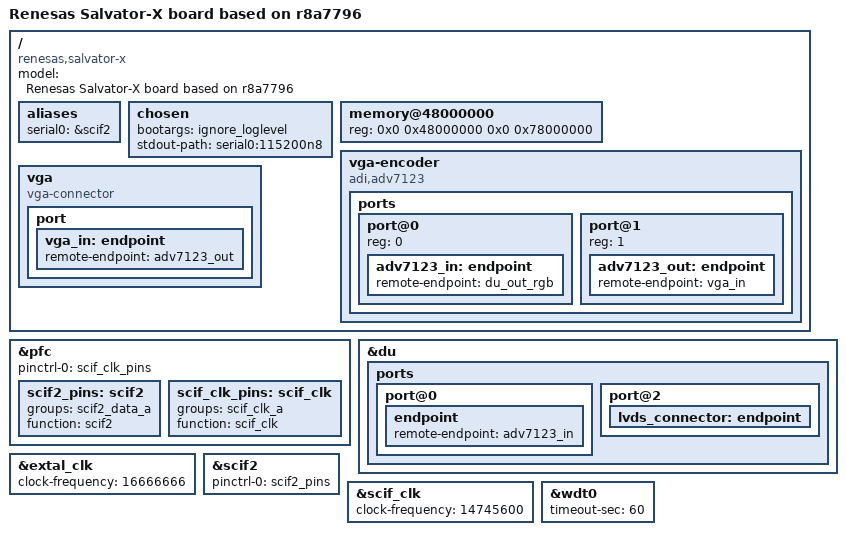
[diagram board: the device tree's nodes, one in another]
/*
 * Device Tree Source for the Salvator-X board
 *
 * Copyright (C) 2016 Renesas Electronics Corp.
 *
 * This file is licensed under the terms of the GNU General Public License
 * version 2.  This program is licensed "as is" without any warranty of any
 * kind, whether express or implied.
 */

/dts-v1/;
#include "r8a7796.dtsi"

/ {
	model = "Renesas Salvator-X board based on r8a7796";
	compatible = "renesas,salvator-x", "renesas,r8a7796";

	aliases {
		serial0 = &scif2;
	};

	chosen {
		bootargs = "ignore_loglevel";
		stdout-path = "serial0:115200n8";
	};

	memory@48000000 {
		device_type = "memory";
		/* first 128MB is reserved for secure area. */
		reg = <0x0 0x48000000 0x0 0x78000000>;
	};

	vga-encoder {
		compatible = "adi,adv7123";

		ports {
			#address-cells = <1>;
			#size-cells = <0>;

			port@0 {
				reg = <0>;
				adv7123_in: endpoint {
					remote-endpoint = <&du_out_rgb>;
				};
			};
			port@1 {
				reg = <1>;
				adv7123_out: endpoint {
					remote-endpoint = <&vga_in>;
				};
			};
		};
	};

	vga {
		compatible = "vga-connector";

		port {
			vga_in: endpoint {
				remote-endpoint = <&adv7123_out>;
			};
		};
	};
};

&pfc {
	pinctrl-0 = <&scif_clk_pins>;
	pinctrl-names = "default";

	scif2_pins: scif2 {
		groups = "scif2_data_a";
		function = "scif2";
	};
	scif_clk_pins: scif_clk {
		groups = "scif_clk_a";
		function = "scif_clk";
	};
};

&du {
	status = "okay";

	ports {
		port@0 {
			endpoint {
				remote-endpoint = <&adv7123_in>;
			};
		};
		port@2 {
			lvds_connector: endpoint {
			};
		};
	};
};

&extal_clk {
	clock-frequency = <16666666>;
};

&scif2 {
	pinctrl-0 = <&scif2_pins>;
	pinctrl-names = "default";
	status = "okay";
};

&scif_clk {
	clock-frequency = <14745600>;
	status = "okay";
};

&wdt0 {
	timeout-sec = <60>;
	status = "okay";
};
